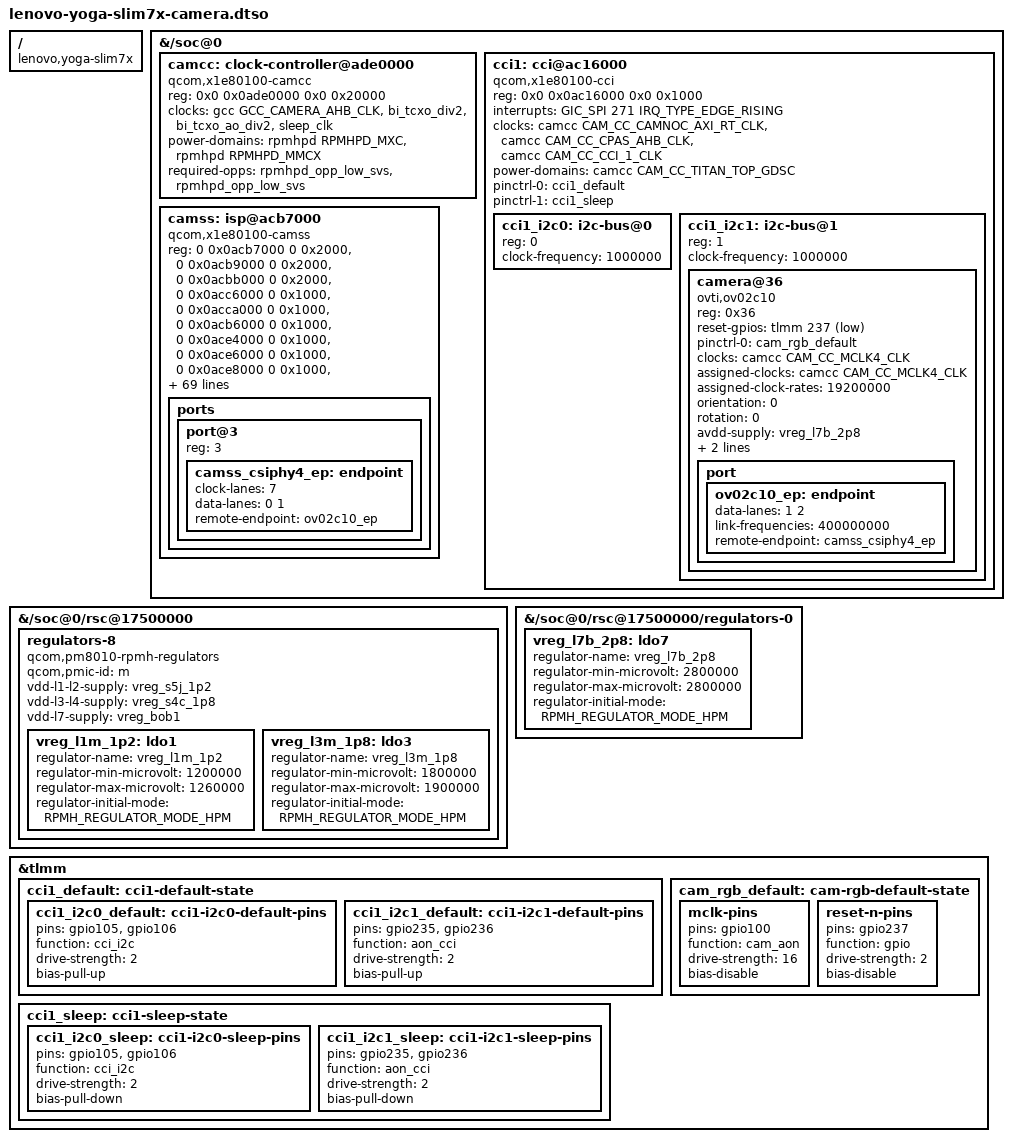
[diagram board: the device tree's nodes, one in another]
/*
 * Lenovo Yoga Slim 7x (X1E80100) camera device-tree overlay.
 *
 * Adds the missing camera ISP wiring on top of a kernel device tree that
 * does not yet carry it upstream (e.g. stock v7.2.x `x1e80100-lenovo-yoga-slim7x.dtb`):
 *
 *   - camcc  : qcom,x1e80100-camcc clock controller (CAM_CC_* clocks, GDSCs)
 *   - cci1   : camera CCI (I2C) controller, enabled, with I2C bus 1
 *   - camss  : qcom,x1e80100-camss ISP (internal CSIPHY model, as implemented
 *              by the mainline v7.2 `qcom-camss` driver and its binding
 *              Documentation/devicetree/bindings/media/qcom,x1e80100-camss.yaml)
 *   - ov02c10 front RGB sensor on CCI1 I2C bus 1 @0x36, CSI lanes on CSIPHY4
 *   - pm8010 camera PMIC regulators (vreg_l1m_1p2, vreg_l3m_1p8) and the
 *     vreg_l7b_2p8 regulator for the sensor A/V power
 *   - CCI1 / sensor pinctrl states
 *
 * Nodes are based on the Linaro arm64-laptops tree and the mainline v7.2
 * CAMSS binding:
 *
 *   https://gitlab.com/Linaro/arm64-laptops/linux.git
 *     branch arm64-laptops-v7.2-rc2-camss-v11
 *
 * Note: the flake's own `x1e80100-linux` kernel already contains these nodes
 * (cherry-picked from the Linaro tree). Only enable this overlay when using a
 * stock kernel whose device tree still lacks the camera nodes, otherwise the
 * nodes would be applied twice.
 */

/dts-v1/;
/plugin/;

/*
 * Declare the boards this overlay applies to, so that NixOS's
 * `deviceTree.applyOverlays` matches it against the target DTB's
 * compatible strings.
 */
/ {
	compatible = "lenovo,yoga-slim7x", "qcom,x1e80100";
};

#include <dt-bindings/gpio/gpio.h>
#include <dt-bindings/interrupt-controller/arm-gic.h>
#include <dt-bindings/clock/qcom,x1e80100-camcc.h>
#include <dt-bindings/clock/qcom,x1e80100-gcc.h>
#include <dt-bindings/interconnect/qcom,icc.h>
#include <dt-bindings/interconnect/qcom,x1e80100-rpmh.h>
#include <dt-bindings/power/qcom,rpmhpd.h>
#include <dt-bindings/regulator/qcom,rpmh-regulator.h>

/ {
	/* CAMCC clock controller - required by camss/cci/sensor clocks and GDSCs */
	fragment@0 {
		target-path = "/soc@0";

		__overlay__ {
			camcc: clock-controller@ade0000 {
				compatible = "qcom,x1e80100-camcc";
				reg = <0x0 0x0ade0000 0x0 0x20000>;
				clocks = <&gcc GCC_CAMERA_AHB_CLK>,
					 <&bi_tcxo_div2>,
					 <&bi_tcxo_ao_div2>,
					 <&sleep_clk>;
				power-domains = <&rpmhpd RPMHPD_MXC>,
						<&rpmhpd RPMHPD_MMCX>;
				required-opps = <&rpmhpd_opp_low_svs>,
						<&rpmhpd_opp_low_svs>;
				#clock-cells = <1>;
				#reset-cells = <1>;
				#power-domain-cells = <1>;
			};
		};
	};

	/* CCI1 I2C controller + OV02C10 RGB camera sensor */
	fragment@1 {
		target-path = "/soc@0";

		__overlay__ {
			cci1: cci@ac16000 {
				compatible = "qcom,x1e80100-cci", "qcom,msm8996-cci";
				reg = <0x0 0x0ac16000 0x0 0x1000>;

				interrupts = <GIC_SPI 271 IRQ_TYPE_EDGE_RISING>;

				clocks = <&camcc CAM_CC_CAMNOC_AXI_RT_CLK>,
					 <&camcc CAM_CC_CPAS_AHB_CLK>,
					 <&camcc CAM_CC_CCI_1_CLK>;
				clock-names = "camnoc_axi",
					      "cpas_ahb",
					      "cci";

				power-domains = <&camcc CAM_CC_TITAN_TOP_GDSC>;

				pinctrl-0 = <&cci1_default>;
				pinctrl-1 = <&cci1_sleep>;
				pinctrl-names = "default", "sleep";

				#address-cells = <1>;
				#size-cells = <0>;

				cci1_i2c0: i2c-bus@0 {
					reg = <0>;
					clock-frequency = <1000000>;
					#address-cells = <1>;
					#size-cells = <0>;
				};

				cci1_i2c1: i2c-bus@1 {
					reg = <1>;
					clock-frequency = <1000000>;
					#address-cells = <1>;
					#size-cells = <0>;

					camera@36 {
						compatible = "ovti,ov02c10";
						reg = <0x36>;

						reset-gpios = <&tlmm 237 GPIO_ACTIVE_LOW>;
						pinctrl-names = "default";
						pinctrl-0 = <&cam_rgb_default>;

						clocks = <&camcc CAM_CC_MCLK4_CLK>;
						assigned-clocks = <&camcc CAM_CC_MCLK4_CLK>;
						assigned-clock-rates = <19200000>;

						orientation = <0>; /* front facing */
						/* NOTE: rotation is 0: the sensor's native readout is
						 * already upright. The upstream Linaro/X1E device trees
						 * use rotation = <180>, but with the ov02c10 driver in
						 * >=6.19/7.2 kernels (whose flip controls use the sensor's
						 * ISP rotate/window engine) libcamera then applies
						 * hflip+vflip to "correct" an already-upright image,
						 * delivering it upside-down. Verified empirically on the
						 * Yoga Slim 7x: flips 0/0 = upright.
						 */
						rotation = <0>;

						avdd-supply = <&vreg_l7b_2p8>;
						dvdd-supply = <&vreg_l1m_1p2>;
						dovdd-supply = <&vreg_l3m_1p8>;

						port {
							ov02c10_ep: endpoint {
								data-lanes = <1 2>;
								link-frequencies = /bits/ 64 <400000000>;
								remote-endpoint = <&camss_csiphy4_ep>;
							};
						};
					};
				};
			};
		};
	};

	/*
	 * CAMSS ISP - internal CSIPHY model, exactly as specified by the
	 * mainline `qcom,x1e80100-camss` binding (v7.2).
	 */
	fragment@2 {
		target-path = "/soc@0";

		__overlay__ {
			camss: isp@acb7000 {
				compatible = "qcom,x1e80100-camss";

				reg = <0 0x0acb7000 0 0x2000>,
				      <0 0x0acb9000 0 0x2000>,
				      <0 0x0acbb000 0 0x2000>,
				      <0 0x0acc6000 0 0x1000>,
				      <0 0x0acca000 0 0x1000>,
				      <0 0x0acb6000 0 0x1000>,
				      <0 0x0ace4000 0 0x1000>,
				      <0 0x0ace6000 0 0x1000>,
				      <0 0x0ace8000 0 0x1000>,
				      <0 0x0acec000 0 0x4000>,
				      <0 0x0acf6000 0 0x1000>,
				      <0 0x0acf7000 0 0x1000>,
				      <0 0x0acf8000 0 0x1000>,
				      <0 0x0ac62000 0 0x4000>,
				      <0 0x0ac71000 0 0x4000>,
				      <0 0x0acc7000 0 0x2000>,
				      <0 0x0accb000 0 0x2000>;

				reg-names = "csid0",
					    "csid1",
					    "csid2",
					    "csid_lite0",
					    "csid_lite1",
					    "csid_wrapper",
					    "csiphy0",
					    "csiphy1",
					    "csiphy2",
					    "csiphy4",
					    "csitpg0",
					    "csitpg1",
					    "csitpg2",
					    "vfe0",
					    "vfe1",
					    "vfe_lite0",
					    "vfe_lite1";

				clocks = <&camcc CAM_CC_CAMNOC_AXI_NRT_CLK>,
					 <&camcc CAM_CC_CAMNOC_AXI_RT_CLK>,
					 <&camcc CAM_CC_CORE_AHB_CLK>,
					 <&camcc CAM_CC_CPAS_AHB_CLK>,
					 <&camcc CAM_CC_CPAS_FAST_AHB_CLK>,
					 <&camcc CAM_CC_CPAS_IFE_0_CLK>,
					 <&camcc CAM_CC_CPAS_IFE_1_CLK>,
					 <&camcc CAM_CC_CPAS_IFE_LITE_CLK>,
					 <&camcc CAM_CC_CPHY_RX_CLK_SRC>,
					 <&camcc CAM_CC_CSID_CLK>,
					 <&camcc CAM_CC_CSID_CSIPHY_RX_CLK>,
					 <&camcc CAM_CC_CSIPHY0_CLK>,
					 <&camcc CAM_CC_CSI0PHYTIMER_CLK>,
					 <&camcc CAM_CC_CSIPHY1_CLK>,
					 <&camcc CAM_CC_CSI1PHYTIMER_CLK>,
					 <&camcc CAM_CC_CSIPHY2_CLK>,
					 <&camcc CAM_CC_CSI2PHYTIMER_CLK>,
					 <&camcc CAM_CC_CSIPHY4_CLK>,
					 <&camcc CAM_CC_CSI4PHYTIMER_CLK>,
					 <&gcc GCC_CAMERA_HF_AXI_CLK>,
					 <&gcc GCC_CAMERA_SF_AXI_CLK>,
					 <&camcc CAM_CC_IFE_0_CLK>,
					 <&camcc CAM_CC_IFE_0_FAST_AHB_CLK>,
					 <&camcc CAM_CC_IFE_1_CLK>,
					 <&camcc CAM_CC_IFE_1_FAST_AHB_CLK>,
					 <&camcc CAM_CC_IFE_LITE_CLK>,
					 <&camcc CAM_CC_IFE_LITE_AHB_CLK>,
					 <&camcc CAM_CC_IFE_LITE_CPHY_RX_CLK>,
					 <&camcc CAM_CC_IFE_LITE_CSID_CLK>;

				clock-names = "camnoc_nrt_axi",
					      "camnoc_rt_axi",
					      "core_ahb",
					      "cpas_ahb",
					      "cpas_fast_ahb",
					      "cpas_vfe0",
					      "cpas_vfe1",
					      "cpas_vfe_lite",
					      "cphy_rx_clk_src",
					      "csid",
					      "csid_csiphy_rx",
					      "csiphy0",
					      "csiphy0_timer",
					      "csiphy1",
					      "csiphy1_timer",
					      "csiphy2",
					      "csiphy2_timer",
					      "csiphy4",
					      "csiphy4_timer",
					      "gcc_axi_hf",
					      "gcc_axi_sf",
					      "vfe0",
					      "vfe0_fast_ahb",
					      "vfe1",
					      "vfe1_fast_ahb",
					      "vfe_lite",
					      "vfe_lite_ahb",
					      "vfe_lite_cphy_rx",
					      "vfe_lite_csid";

				interrupts = <GIC_SPI 464 IRQ_TYPE_EDGE_RISING>,
					     <GIC_SPI 466 IRQ_TYPE_EDGE_RISING>,
					     <GIC_SPI 431 IRQ_TYPE_EDGE_RISING>,
					     <GIC_SPI 468 IRQ_TYPE_EDGE_RISING>,
					     <GIC_SPI 359 IRQ_TYPE_EDGE_RISING>,
					     <GIC_SPI 477 IRQ_TYPE_EDGE_RISING>,
					     <GIC_SPI 478 IRQ_TYPE_EDGE_RISING>,
					     <GIC_SPI 479 IRQ_TYPE_EDGE_RISING>,
					     <GIC_SPI 122 IRQ_TYPE_EDGE_RISING>,
					     <GIC_SPI 465 IRQ_TYPE_EDGE_RISING>,
					     <GIC_SPI 467 IRQ_TYPE_EDGE_RISING>,
					     <GIC_SPI 469 IRQ_TYPE_EDGE_RISING>,
					     <GIC_SPI 360 IRQ_TYPE_EDGE_RISING>;

				interrupt-names = "csid0",
						  "csid1",
						  "csid2",
						  "csid_lite0",
						  "csid_lite1",
						  "csiphy0",
						  "csiphy1",
						  "csiphy2",
						  "csiphy4",
						  "vfe0",
						  "vfe1",
						  "vfe_lite0",
						  "vfe_lite1";

				interconnects = <&gem_noc MASTER_APPSS_PROC QCOM_ICC_TAG_ACTIVE_ONLY
						 &config_noc SLAVE_CAMERA_CFG QCOM_ICC_TAG_ACTIVE_ONLY>,
						<&mmss_noc MASTER_CAMNOC_HF QCOM_ICC_TAG_ALWAYS
						 &mc_virt SLAVE_EBI1 QCOM_ICC_TAG_ALWAYS>,
						<&mmss_noc MASTER_CAMNOC_SF QCOM_ICC_TAG_ALWAYS
						 &mc_virt SLAVE_EBI1 QCOM_ICC_TAG_ALWAYS>,
						<&mmss_noc MASTER_CAMNOC_ICP QCOM_ICC_TAG_ALWAYS
						 &mc_virt SLAVE_EBI1 QCOM_ICC_TAG_ALWAYS>;

				interconnect-names = "ahb",
						     "hf_mnoc",
						     "sf_mnoc",
						     "sf_icp_mnoc";

				iommus = <&apps_smmu 0x800 0x60>,
					 <&apps_smmu 0x860 0x60>,
					 <&apps_smmu 0x1800 0x60>,
					 <&apps_smmu 0x1860 0x60>,
					 <&apps_smmu 0x18e0 0x00>,
					 <&apps_smmu 0x1980 0x20>,
					 <&apps_smmu 0x1900 0x00>,
					 <&apps_smmu 0x19a0 0x20>;

				power-domains = <&camcc CAM_CC_IFE_0_GDSC>,
						<&camcc CAM_CC_IFE_1_GDSC>,
						<&camcc CAM_CC_TITAN_TOP_GDSC>;

				power-domain-names = "ife0",
						     "ife1",
						     "top";

				vdd-csiphy-0p8-supply = <&vreg_l2c_0p8>;
				vdd-csiphy-1p2-supply = <&vreg_l1c_1p2>;

				ports {
					#address-cells = <1>;
					#size-cells = <0>;

					/*
					 * port0 => csiphy0
					 * port1 => csiphy1
					 * port2 => csiphy2
					 * port3 => csiphy4
					 */
					port@3 {
						reg = <3>;

						camss_csiphy4_ep: endpoint {
							clock-lanes = <7>;
							data-lanes = <0 1>;
							remote-endpoint = <&ov02c10_ep>;
						};
					};
				};
			};
		};
	};

	/* pm8010 camera PMIC regulators (dvdd/doovdd rails for the RGB sensor) */
	fragment@3 {
		target-path = "/soc@0/rsc@17500000";

		__overlay__ {
			regulators-8 {
				compatible = "qcom,pm8010-rpmh-regulators";
				qcom,pmic-id = "m";

				vdd-l1-l2-supply = <&vreg_s5j_1p2>;
				vdd-l3-l4-supply = <&vreg_s4c_1p8>;
				vdd-l7-supply = <&vreg_bob1>;

				vreg_l1m_1p2: ldo1 {
					regulator-name = "vreg_l1m_1p2";
					regulator-min-microvolt = <1200000>;
					regulator-max-microvolt = <1260000>;
					regulator-initial-mode = <RPMH_REGULATOR_MODE_HPM>;
				};

				vreg_l3m_1p8: ldo3 {
					regulator-name = "vreg_l3m_1p8";
					regulator-min-microvolt = <1800000>;
					regulator-max-microvolt = <1900000>;
					regulator-initial-mode = <RPMH_REGULATOR_MODE_HPM>;
				};
			};
		};
	};

	/* vreg_l7b_2p8: 2.8V RGB camera analog supply (main PMIC ldo7) */
	fragment@4 {
		target-path = "/soc@0/rsc@17500000/regulators-0";

		__overlay__ {
			vreg_l7b_2p8: ldo7 {
				regulator-name = "vreg_l7b_2p8";
				regulator-min-microvolt = <2800000>;
				regulator-max-microvolt = <2800000>;
				regulator-initial-mode = <RPMH_REGULATOR_MODE_HPM>;
			};
		};
	};

	/* CCI1 + camera sensor pin configurations */
	fragment@5 {
		target = <&tlmm>;

		__overlay__ {
			cci1_default: cci1-default-state {
				cci1_i2c0_default: cci1-i2c0-default-pins {
					/* cci_i2c_sda2, cci_i2c_scl2 */
					pins = "gpio105", "gpio106";
					function = "cci_i2c";
					drive-strength = <2>;
					bias-pull-up;
				};

				cci1_i2c1_default: cci1-i2c1-default-pins {
					/* aon_cci_i2c_sda3, aon_cci_i2c_scl3 */
					pins = "gpio235", "gpio236";
					function = "aon_cci";
					drive-strength = <2>;
					bias-pull-up;
				};
			};

			cci1_sleep: cci1-sleep-state {
				cci1_i2c0_sleep: cci1-i2c0-sleep-pins {
					/* cci_i2c_sda2, cci_i2c_scl2 */
					pins = "gpio105", "gpio106";
					function = "cci_i2c";
					drive-strength = <2>;
					bias-pull-down;
				};

				cci1_i2c1_sleep: cci1-i2c1-sleep-pins {
					/* aon_cci_i2c_sda3, aon_cci_i2c_scl3 */
					pins = "gpio235", "gpio236";
					function = "aon_cci";
					drive-strength = <2>;
					bias-pull-down;
				};
			};

			cam_rgb_default: cam-rgb-default-state {
				mclk-pins {
					pins = "gpio100";
					function = "cam_aon";
					drive-strength = <16>;
					bias-disable;
				};

				reset-n-pins {
					pins = "gpio237";
					function = "gpio";
					drive-strength = <2>;
					bias-disable;
				};
			};
		};
	};
};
